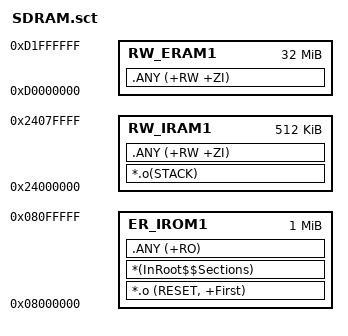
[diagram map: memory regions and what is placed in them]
;本文件用于备份sct文件的配置，要使用时把本文件名改为“SDRAM.sct”
;然后复制到Output目录即可。
; *************************************************************
; *** Scatter-Loading Description File generated by uVision ***
; *************************************************************

LR_IROM1 0x08000000 0x00100000  {    ; load region size_region
  ER_IROM1 0x08000000 0x00100000  {  ; load address = execution address
   *.o (RESET, +First)
   *(InRoot$$Sections)
   .ANY (+RO)
  }
  
  
  RW_IRAM1 0x24000000 0x80000  {  ; 内部SRAM
	*.o(STACK)				;选择栈区
;  stm32h7xx_hal_rcc.o(+RW)	;选择stm32h7xx_hal_rcc的RW内容
;  stm32h7xx_hal_rcc_ex.o(+RW)	;选择stm32h7xx_hal_rcc_ex的RW内容
	.ANY (+RW +ZI)			;其余的RW/ZI-data都分配到这里
  }
  
  RW_ERAM1 0xD0000000 0x02000000 {  ; 外部SDRAM  
   .ANY (+RW +ZI)				;选择EXRAM节区

  }
}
